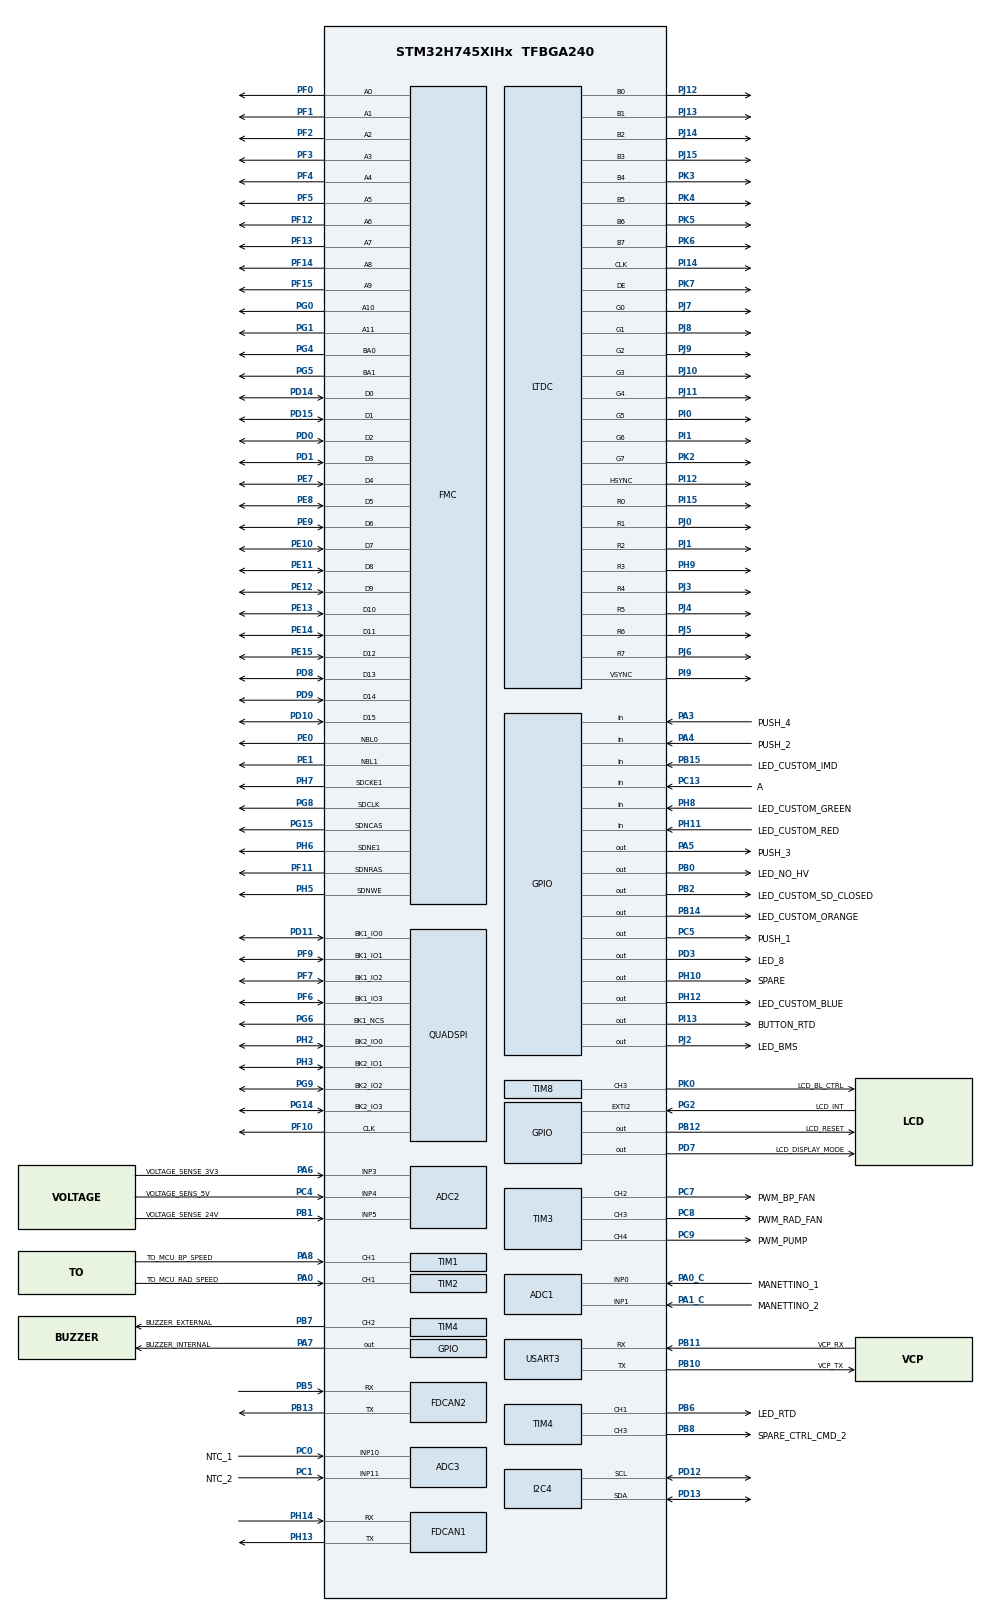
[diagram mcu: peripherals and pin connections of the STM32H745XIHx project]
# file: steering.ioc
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ADC1.Channel-1\#ChannelRegularConversion=ADC_CHANNEL_1
ADC1.NbrOfConversionFlag=1
ADC1.OffsetNumber-1\#ChannelRegularConversion=ADC_OFFSET_NONE
ADC1.OffsetSignedSaturation-1\#ChannelRegularConversion=DISABLE
ADC1.Rank-1\#ChannelRegularConversion=1
ADC1.SamplingTime-1\#ChannelRegularConversion=ADC_SAMPLETIME_1CYCLE_5
ADC1.master=1
ADC2.Channel-0\#ChannelRegularConversion=ADC_CHANNEL_3
ADC2.NbrOfConversionFlag=1
ADC2.OffsetNumber-0\#ChannelRegularConversion=ADC_OFFSET_NONE
ADC2.OffsetSignedSaturation-0\#ChannelRegularConversion=DISABLE
ADC2.Rank-0\#ChannelRegularConversion=1
ADC2.SamplingTime-0\#ChannelRegularConversion=ADC_SAMPLETIME_1CYCLE_5
ADC3.Channel-0\#ChannelRegularConversion=ADC_CHANNEL_10
ADC3.NbrOfConversionFlag=1
ADC3.OffsetNumber-0\#ChannelRegularConversion=ADC_OFFSET_NONE
ADC3.OffsetSignedSaturation-0\#ChannelRegularConversion=DISABLE
ADC3.Rank-0\#ChannelRegularConversion=1
ADC3.SamplingTime-0\#ChannelRegularConversion=ADC_SAMPLETIME_1CYCLE_5
CORTEX_M7.AccessPermission-Cortex_Memory_Protection_Unit_Region1_Settings=MPU_REGION_FULL_ACCESS
CORTEX_M7.AccessPermission-Cortex_Memory_Protection_Unit_Region2_Settings=MPU_REGION_FULL_ACCESS
CORTEX_M7.BaseAddress-Cortex_Memory_Protection_Unit_Region1_Settings=0xD0000000
CORTEX_M7.BaseAddress-Cortex_Memory_Protection_Unit_Region2_Settings=0x90000000
CORTEX_M7.CPU_DCache=Enabled
CORTEX_M7.CPU_ICache=Enabled
CORTEX_M7.DisableExec-Cortex_Memory_Protection_Unit_Region0_Settings=MPU_INSTRUCTION_ACCESS_DISABLE
CORTEX_M7.DisableExec-Cortex_Memory_Protection_Unit_Region2_Settings=MPU_INSTRUCTION_ACCESS_DISABLE
CORTEX_M7.Enable-Cortex_Memory_Protection_Unit_Region0_Settings=MPU_REGION_ENABLE
CORTEX_M7.Enable-Cortex_Memory_Protection_Unit_Region1_Settings=MPU_REGION_ENABLE
CORTEX_M7.Enable-Cortex_Memory_Protection_Unit_Region2_Settings=MPU_REGION_ENABLE
CORTEX_M7.IsBufferable-Cortex_Memory_Protection_Unit_Region2_Settings=MPU_ACCESS_BUFFERABLE
CORTEX_M7.IsCacheable-Cortex_Memory_Protection_Unit_Region1_Settings=MPU_ACCESS_CACHEABLE
CORTEX_M7.IsCacheable-Cortex_Memory_Protection_Unit_Region2_Settings=MPU_ACCESS_CACHEABLE
CORTEX_M7.IsShareable-Cortex_Memory_Protection_Unit_Region0_Settings=MPU_ACCESS_SHAREABLE
CORTEX_M7.IsShareable-Cortex_Memory_Protection_Unit_Region2_Settings=MPU_ACCESS_SHAREABLE
CORTEX_M7.MPU_Control=MPU_PRIVILEGED_DEFAULT
CORTEX_M7.Size-Cortex_Memory_Protection_Unit_Region0_Settings=MPU_REGION_SIZE_4GB
CORTEX_M7.Size-Cortex_Memory_Protection_Unit_Region1_Settings=MPU_REGION_SIZE_32MB
CORTEX_M7.Size-Cortex_Memory_Protection_Unit_Region2_Settings=MPU_REGION_SIZE_128MB
CORTEX_M7.SubRegionDisable-Cortex_Memory_Protection_Unit_Region0_Settings=0x87
CORTEX_M7.TypeExtField-Cortex_Memory_Protection_Unit_Region2_Settings=MPU_TEX_LEVEL1
CortexM4.IPs=FATFS_M4\:I,FREERTOS_M4\:I,IWDG2\:I,RCC,USB_DEVICE_M4\:I,USB_HOST_M4\:I,WWDG2\:I,DMA,BDMA,MDMA,NVIC2\:I,DEBUG,PDM2PCM_M4\:I,PWR,RESMGR_UTILITY,SYS_M4\:I,CORTEX_M4\:I,OPENAMP_M4\:I,VREFBUF,GPIO
CortexM4.Pins=PD3
CortexM7.IPs=FATFS_M7\:I,FREERTOS_M7\:I,IWDG1\:I,RCC\:I,USB_DEVICE_M7\:I,USB_HOST_M7\:I,WWDG1\:I,DMA\:I,BDMA\:I,MDMA\:I,NVIC1\:I,CORTEX_M7\:I,DEBUG\:I,PDM2PCM_M7\:I,PWR\:I,RESMGR_UTILITY\:I,SYS\:I,OPENAMP_M7\:I,VREFBUF\:I,QUADSPI\:I,USART3\:I,LTDC\:I,FMC\:I,TIM8\:I,DMA2D\:I,I2C4\:I,GPIO\:I,FDCAN2\:I,FDCAN1\:I,TIM1\:I,TIM2\:I,TIM3\:I,TIM4\:I,ADC1\:I,ADC2\:I,ADC3\:I
CortexM7.Pins=PD7,PC13,PI13,PG2,PJ2,PB12
FDCAN1.CalculateBaudRateNominal=1499999
FDCAN1.CalculateTimeBitNominal=666
FDCAN1.CalculateTimeQuantumNominal=133.33333333333334
FDCAN2.CalculateBaudRateNominal=1499999
FDCAN2.CalculateTimeBitNominal=666
FDCAN2.CalculateTimeQuantumNominal=133.33333333333334
FMC.CASLatency1=FMC_SDRAM_CAS_LATENCY_3
FMC.ExitSelfRefreshDelay1=7
FMC.LoadToActiveDelay1=2
FMC.RCDDelay1=2
FMC.RPDelay1=2
FMC.ReadBurst1=FMC_SDRAM_RBURST_ENABLE
FMC.RowCycleDelay1=7
FMC.SDClockPeriod1=FMC_SDRAM_CLOCK_PERIOD_2
FMC.SelfRefreshTime1=4
FMC.WriteRecoveryTime1=3
I2C4.CustomTiming=Disabled
I2C4.Speed=100
I2C4.Timing=0x307075B1
LTDC.ActiveH=272
LTDC.ActiveW=480
LTDC.Alpha_L0=255
LTDC.BlendingFactor1_L0=LTDC_BLENDING_FACTOR1_PAxCA
LTDC.BlendingFactor2_L0=LTDC_BLENDING_FACTOR2_PAxCA
LTDC.Blue=255
LTDC.FBStartAdress_L0=0xd0000000
LTDC.Green=255
LTDC.Green_L0=0
LTDC.HBP=13
LTDC.HFP=32
LTDC.HSync=41
LTDC.ImageHeight_L0=272
LTDC.ImageWidth_L0=480
LTDC.Layers=0
LTDC.Red=0
LTDC.VSync=10
LTDC.WindowX1_L0=480
LTDC.WindowY1_L0=272
Mcu.Family=STM32H7
Mcu.Name=STM32H745XIHx
Mcu.Package=TFBGA240
Mdma.MDMA_Channel0.Request0=SW
Mdma.MDMA_Channel0.RequestsNb=1
Mdma.MDMA_Channel0.SW.0.BlockCount=0
Mdma.MDMA_Channel0.SW.0.BlockDataLength=0
Mdma.MDMA_Channel0.SW.0.BufferTransferLength=128
Mdma.MDMA_Channel0.SW.0.CircularMode=MDMA_LINEAR_LIST
Mdma.MDMA_Channel0.SW.0.DataAlignment=MDMA_DATAALIGN_PACKENABLE
Mdma.MDMA_Channel0.SW.0.DestBlockAddressOffset=0
Mdma.MDMA_Channel0.SW.0.DestBurst=MDMA_DEST_BURST_SINGLE
Mdma.MDMA_Channel0.SW.0.DestDataSize=MDMA_DEST_DATASIZE_WORD
Mdma.MDMA_Channel0.SW.0.DestinationInc=MDMA_DEST_INC_WORD
Mdma.MDMA_Channel0.SW.0.DstAddress=0
Mdma.MDMA_Channel0.SW.0.Endianness=MDMA_LITTLE_ENDIANNESS_PRESERVE
Mdma.MDMA_Channel0.SW.0.Instance=MDMA_Channel0
Mdma.MDMA_Channel0.SW.0.MaskAddress=0
Mdma.MDMA_Channel0.SW.0.MaskData=0
Mdma.MDMA_Channel0.SW.0.Priority=MDMA_PRIORITY_HIGH
Mdma.MDMA_Channel0.SW.0.Rank=First
Mdma.MDMA_Channel0.SW.0.SourceBlockAddressOffset=0
Mdma.MDMA_Channel0.SW.0.SourceBurst=MDMA_SOURCE_BURST_SINGLE
Mdma.MDMA_Channel0.SW.0.SourceDataSize=MDMA_SRC_DATASIZE_WORD
Mdma.MDMA_Channel0.SW.0.SourceInc=MDMA_SRC_INC_WORD
Mdma.MDMA_Channel0.SW.0.SrcAddress=0
Mdma.MDMA_Channel0.SW.0.TransferTriggerMode=MDMA_BLOCK_TRANSFER
Mdma.RequestSet0=MDMA_Channel0
Mdma.RequestSetsNb=1
NVIC1.EXTI2_IRQn=true\:0\:0\:false\:false\:true\:true\:true\:true
NVIC1.MDMA_IRQn=true\:0\:0\:false\:false\:true\:false\:true\:true
NVIC1.PriorityGroup=NVIC_PRIORITYGROUP_4
NVIC1.QUADSPI_IRQn=true\:15\:0\:true\:false\:true\:true\:true\:true
NVIC2.PriorityGroup=NVIC_PRIORITYGROUP_4
PA0.GPIO_Label=TO_MCU_RAD_SPEED
PA0.PinAttribute=CortexM7
PA0.Signal=S_TIM2_CH1_ETR
PA0_C.GPIO_Label=MANETTINO_1
PA0_C.PinAttribute=CortexM7
PA0_C.Signal=ADCx_INP0
PA13\ (JTMS/SWDIO).Mode=JTAG_4_pins
PA13\ (JTMS/SWDIO).PinAttribute=CortexM7
PA13\ (JTMS/SWDIO).Signal=DEBUG_JTMS-SWDIO
PA14\ (JTCK/SWCLK).Mode=JTAG_4_pins
PA14\ (JTCK/SWCLK).PinAttribute=CortexM7
PA14\ (JTCK/SWCLK).Signal=DEBUG_JTCK-SWCLK
PA15\ (JTDI).Mode=JTAG_4_pins
PA15\ (JTDI).PinAttribute=CortexM7
PA15\ (JTDI).Signal=DEBUG_JTDI
PA1_C.GPIO_Label=MANETTINO_2
PA1_C.PinAttribute=CortexM7
PA1_C.Signal=ADCx_INP1
PA3.GPIO_Label=PUSH_4
PA3.PinAttribute=Free
PA3.Signal=GPIO_Input
PA4.GPIO_Label=PUSH_2
PA4.PinAttribute=Free
PA4.Signal=GPIO_Input
PA5.GPIO_Label=PUSH_3
PA5.PinAttribute=Free
PA5.Signal=GPIO_Output
PA6.GPIO_Label=VOLTAGE_SENSE_3V3
PA6.PinAttribute=CortexM7
PA6.Signal=ADCx_INP3
PA7.GPIO_Label=BUZZER_INTERNAL
PA7.PinAttribute=Free
PA7.Signal=GPIO_Output
PA8.GPIO_Label=TO_MCU_BP_SPEED
PA8.PinAttribute=CortexM7
PA8.Signal=S_TIM1_CH1
PB0.GPIO_Label=LED_NO_HV
PB0.PinAttribute=Free
PB0.Signal=GPIO_Output
PB1.GPIO_Label=VOLTAGE_SENSE_24V
PB1.PinAttribute=CortexM7
PB1.Signal=ADCx_INP5
PB10.GPIO_Label=VCP_TX
PB10.Mode=Asynchronous
PB10.PinAttribute=CortexM7
PB10.Signal=USART3_TX
PB11.GPIO_Label=VCP_RX
PB11.Mode=Asynchronous
PB11.PinAttribute=CortexM7
PB11.Signal=USART3_RX
PB12.GPIO_Label=LCD_RESET
PB12.PinAttribute=CortexM7
PB12.PinState=GPIO_PIN_SET
PB12.Signal=GPIO_Output
PB13.Mode=FDCAN_Activate
PB13.PinAttribute=CortexM7
PB13.Signal=FDCAN2_TX
PB14.GPIO_Label=LED_CUSTOM_ORANGE
PB14.PinAttribute=Free
PB14.Signal=GPIO_Output
PB15.GPIO_Label=LED_CUSTOM_IMD
PB15.PinAttribute=Free
PB15.Signal=GPIO_Input
PB2.GPIO_Label=LED_CUSTOM_SD_CLOSED
PB2.PinAttribute=Free
PB2.Signal=GPIO_Output
PB3\ (JTDO/TRACESWO).Mode=JTAG_4_pins
PB3\ (JTDO/TRACESWO).PinAttribute=CortexM7
PB3\ (JTDO/TRACESWO).Signal=DEBUG_JTDO-SWO
PB5.Mode=FDCAN_Activate
PB5.PinAttribute=CortexM7
PB5.Signal=FDCAN2_RX
PB6.GPIO_Label=LED_RTD
PB6.PinAttribute=CortexM7
PB6.Signal=S_TIM4_CH1
PB7.GPIO_Label=BUZZER_EXTERNAL
PB7.PinAttribute=CortexM7
PB7.Signal=S_TIM4_CH2
PB8.GPIO_Label=SPARE_CTRL_CMD_2
PB8.PinAttribute=CortexM7
PB8.Signal=S_TIM4_CH3
PC0.GPIO_Label=NTC_1
PC0.PinAttribute=CortexM7
PC0.Signal=ADCx_INP10
PC1.GPIO_Label=NTC_2
PC1.PinAttribute=CortexM7
PC1.Signal=ADCx_INP11
PC13.GPIO_Label=A
PC13.PinAttribute=CortexM7
PC13.Signal=GPIO_Input
PC14-OSC32_IN\ (OSC32_IN).GPIO_Label=OSC32_IN
PC14-OSC32_IN\ (OSC32_IN).Mode=LSE-External-Clock-Source
PC14-OSC32_IN\ (OSC32_IN).PinAttribute=CortexM7
PC14-OSC32_IN\ (OSC32_IN).Signal=RCC_OSC32_IN
PC4.GPIO_Label=VOLTAGE_SENS_5V
PC4.PinAttribute=CortexM7
PC4.Signal=ADCx_INP4
PC5.GPIO_Label=PUSH_1
PC5.PinAttribute=Free
PC5.Signal=GPIO_Output
PC7.GPIO_Label=PWM_BP_FAN
PC7.PinAttribute=CortexM7
PC7.Signal=S_TIM3_CH2
PC8.GPIO_Label=PWM_RAD_FAN
PC8.PinAttribute=CortexM7
PC8.Signal=S_TIM3_CH3
PC9.GPIO_Label=PWM_PUMP
PC9.PinAttribute=CortexM7
PC9.Signal=S_TIM3_CH4
PD0.PinAttribute=CortexM7
PD0.Signal=FMC_D2_DA2
PD1.PinAttribute=CortexM7
PD1.Signal=FMC_D3_DA3
PD10.PinAttribute=CortexM7
PD10.Signal=FMC_D15_DA15
PD11.GPIO_Speed=GPIO_SPEED_FREQ_VERY_HIGH
PD11.Mode=Dual_Bank
PD11.PinAttribute=CortexM7
PD11.Signal=QUADSPI_BK1_IO0
PD12.Mode=I2C
PD12.PinAttribute=CortexM7
PD12.Signal=I2C4_SCL
PD13.Mode=I2C
PD13.PinAttribute=CortexM7
PD13.Signal=I2C4_SDA
PD14.PinAttribute=CortexM7
PD14.Signal=FMC_D0_DA0
PD15.PinAttribute=CortexM7
PD15.Signal=FMC_D1_DA1
PD3.GPIO_Label=LED_8
PD3.PinAttribute=CortexM4
PD3.Signal=GPIO_Output
PD7.GPIO_Label=LCD_DISPLAY_MODE
PD7.GPIO_Speed=GPIO_SPEED_FREQ_LOW
PD7.PinAttribute=CortexM7
PD7.PinState=GPIO_PIN_SET
PD7.Signal=GPIO_Output
PD8.PinAttribute=CortexM7
PD8.Signal=FMC_D13_DA13
PD9.PinAttribute=CortexM7
PD9.Signal=FMC_D14_DA14
PE0.PinAttribute=CortexM7
PE0.Signal=FMC_NBL0
PE1.PinAttribute=CortexM7
PE1.Signal=FMC_NBL1
PE10.PinAttribute=CortexM7
PE10.Signal=FMC_D7_DA7
PE11.PinAttribute=CortexM7
PE11.Signal=FMC_D8_DA8
PE12.PinAttribute=CortexM7
PE12.Signal=FMC_D9_DA9
PE13.PinAttribute=CortexM7
PE13.Signal=FMC_D10_DA10
PE14.PinAttribute=CortexM7
PE14.Signal=FMC_D11_DA11
PE15.PinAttribute=CortexM7
PE15.Signal=FMC_D12_DA12
PE7.PinAttribute=CortexM7
PE7.Signal=FMC_D4_DA4
PE8.PinAttribute=CortexM7
PE8.Signal=FMC_D5_DA5
PE9.PinAttribute=CortexM7
PE9.Signal=FMC_D6_DA6
PF0.PinAttribute=CortexM7
PF0.Signal=FMC_A0
PF1.PinAttribute=CortexM7
PF1.Signal=FMC_A1
PF10.GPIO_Speed=GPIO_SPEED_FREQ_VERY_HIGH
PF10.Mode=Dual_Bank
PF10.PinAttribute=CortexM7
PF10.Signal=QUADSPI_CLK
PF11.PinAttribute=CortexM7
PF11.Signal=FMC_SDNRAS
PF12.PinAttribute=CortexM7
PF12.Signal=FMC_A6
PF13.PinAttribute=CortexM7
PF13.Signal=FMC_A7
PF14.PinAttribute=CortexM7
PF14.Signal=FMC_A8
PF15.PinAttribute=CortexM7
PF15.Signal=FMC_A9
PF2.PinAttribute=CortexM7
PF2.Signal=FMC_A2
PF3.PinAttribute=CortexM7
PF3.Signal=FMC_A3
PF4.PinAttribute=CortexM7
PF4.Signal=FMC_A4
PF5.PinAttribute=CortexM7
PF5.Signal=FMC_A5
PF6.GPIO_Speed=GPIO_SPEED_FREQ_VERY_HIGH
PF6.Mode=Dual_Bank
PF6.PinAttribute=CortexM7
PF6.Signal=QUADSPI_BK1_IO3
PF7.GPIO_Speed=GPIO_SPEED_FREQ_VERY_HIGH
PF7.Mode=Dual_Bank
PF7.PinAttribute=CortexM7
PF7.Signal=QUADSPI_BK1_IO2
PF9.GPIO_Speed=GPIO_SPEED_FREQ_VERY_HIGH
PF9.Mode=Dual_Bank
PF9.PinAttribute=CortexM7
PF9.Signal=QUADSPI_BK1_IO1
PG0.PinAttribute=CortexM7
PG0.Signal=FMC_A10
PG1.PinAttribute=CortexM7
PG1.Signal=FMC_A11
PG14.GPIO_Speed=GPIO_SPEED_FREQ_VERY_HIGH
PG14.Mode=Dual_Bank
PG14.PinAttribute=CortexM7
PG14.Signal=QUADSPI_BK2_IO3
PG15.PinAttribute=CortexM7
PG15.Signal=FMC_SDNCAS
PG2.GPIO_Label=LCD_INT
PG2.PinAttribute=CortexM7
PG2.Signal=GPXTI2
PG4.PinAttribute=CortexM7
PG4.Signal=FMC_A14_BA0
PG5.PinAttribute=CortexM7
PG5.Signal=FMC_A15_BA1
PG6.GPIO_PuPd=GPIO_PULLUP
PG6.GPIO_Speed=GPIO_SPEED_FREQ_VERY_HIGH
PG6.Mode=Enable Chip Select 1 for both banks
PG6.PinAttribute=CortexM7
PG6.Signal=QUADSPI_BK1_NCS
PG8.PinAttribute=CortexM7
PG8.Signal=FMC_SDCLK
PG9.GPIO_Speed=GPIO_SPEED_FREQ_VERY_HIGH
PG9.Mode=Dual_Bank
PG9.PinAttribute=CortexM7
PG9.Signal=QUADSPI_BK2_IO2
PH0-OSC_IN\ (PH0).GPIO_Label=OSC_IN
PH0-OSC_IN\ (PH0).Mode=HSE-External-Clock-Source
PH0-OSC_IN\ (PH0).PinAttribute=CortexM7
PH0-OSC_IN\ (PH0).Signal=RCC_OSC_IN
PH10.GPIO_Label=SPARE
PH10.PinAttribute=Free
PH10.Signal=GPIO_Output
PH11.GPIO_Label=LED_CUSTOM_RED
PH11.PinAttribute=Free
PH11.Signal=GPIO_Input
PH12.GPIO_Label=LED_CUSTOM_BLUE
PH12.PinAttribute=Free
PH12.Signal=GPIO_Output
PH13.Mode=FDCAN_Activate
PH13.PinAttribute=CortexM7
PH13.Signal=FDCAN1_TX
PH14.Mode=FDCAN_Activate
PH14.PinAttribute=CortexM7
PH14.Signal=FDCAN1_RX
PH2.GPIO_Speed=GPIO_SPEED_FREQ_VERY_HIGH
PH2.Mode=Dual_Bank
PH2.PinAttribute=CortexM7
PH2.Signal=QUADSPI_BK2_IO0
PH3.GPIO_Speed=GPIO_SPEED_FREQ_VERY_HIGH
PH3.Mode=Dual_Bank
PH3.PinAttribute=CortexM7
PH3.Signal=QUADSPI_BK2_IO1
PH5.PinAttribute=CortexM7
PH5.Signal=FMC_SDNWE
PH6.Mode=SdramChipSelect2_1
PH6.PinAttribute=CortexM7
PH6.Signal=FMC_SDNE1
PH7.Mode=SdramChipSelect2_1
PH7.PinAttribute=CortexM7
PH7.Signal=FMC_SDCKE1
PH8.GPIO_Label=LED_CUSTOM_GREEN
PH8.PinAttribute=Free
PH8.Signal=GPIO_Input
PH9.Mode=RGB888
PH9.PinAttribute=CortexM7
PH9.Signal=LTDC_R3
PI0.Mode=RGB888
PI0.PinAttribute=CortexM7
PI0.Signal=LTDC_G5
PI1.Mode=RGB888
PI1.PinAttribute=CortexM7
PI1.Signal=LTDC_G6
PI12.Mode=RGB888
PI12.PinAttribute=CortexM7
PI12.Signal=LTDC_HSYNC
PI13.GPIO_Label=BUTTON_RTD
PI13.PinAttribute=CortexM7
PI13.Signal=GPIO_Output
PI14.Mode=RGB888
PI14.PinAttribute=CortexM7
PI14.Signal=LTDC_CLK
PI15.Mode=RGB888
PI15.PinAttribute=CortexM7
PI15.Signal=LTDC_R0
PI9.Mode=RGB888
PI9.PinAttribute=CortexM7
PI9.Signal=LTDC_VSYNC
PJ0.Mode=RGB888
PJ0.PinAttribute=CortexM7
PJ0.Signal=LTDC_R1
PJ1.Mode=RGB888
PJ1.PinAttribute=CortexM7
PJ1.Signal=LTDC_R2
PJ10.Mode=RGB888
PJ10.PinAttribute=CortexM7
PJ10.Signal=LTDC_G3
PJ11.Mode=RGB888
PJ11.PinAttribute=CortexM7
PJ11.Signal=LTDC_G4
PJ12.Mode=RGB888
PJ12.PinAttribute=CortexM7
PJ12.Signal=LTDC_B0
PJ13.Mode=RGB888
PJ13.PinAttribute=CortexM7
PJ13.Signal=LTDC_B1
PJ14.Mode=RGB888
PJ14.PinAttribute=CortexM7
PJ14.Signal=LTDC_B2
PJ15.Mode=RGB888
PJ15.PinAttribute=CortexM7
PJ15.Signal=LTDC_B3
PJ2.GPIO_Label=LED_BMS
PJ2.PinAttribute=CortexM7
PJ2.Signal=GPIO_Output
PJ3.Mode=RGB888
PJ3.PinAttribute=CortexM7
PJ3.Signal=LTDC_R4
PJ4.Mode=RGB888
PJ4.PinAttribute=CortexM7
PJ4.Signal=LTDC_R5
PJ5.Mode=RGB888
PJ5.PinAttribute=CortexM7
PJ5.Signal=LTDC_R6
PJ6.Mode=RGB888
PJ6.PinAttribute=CortexM7
PJ6.Signal=LTDC_R7
PJ7.Mode=RGB888
PJ7.PinAttribute=CortexM7
PJ7.Signal=LTDC_G0
PJ8.Mode=RGB888
PJ8.PinAttribute=CortexM7
PJ8.Signal=LTDC_G1
PJ9.Mode=RGB888
PJ9.PinAttribute=CortexM7
PJ9.Signal=LTDC_G2
PK0.GPIO_Label=LCD_BL_CTRL
PK0.GPIO_Speed=GPIO_SPEED_FREQ_MEDIUM
PK0.PinAttribute=CortexM7
PK0.Signal=S_TIM8_CH3
PK2.Mode=RGB888
PK2.PinAttribute=CortexM7
PK2.Signal=LTDC_G7
PK3.Mode=RGB888
PK3.PinAttribute=CortexM7
PK3.Signal=LTDC_B4
PK4.Mode=RGB888
PK4.PinAttribute=CortexM7
PK4.Signal=LTDC_B5
PK5.Mode=RGB888
PK5.PinAttribute=CortexM7
PK5.Signal=LTDC_B6
PK6.Mode=RGB888
PK6.PinAttribute=CortexM7
PK6.Signal=LTDC_B7
PK7.Mode=RGB888
PK7.PinAttribute=CortexM7
PK7.Signal=LTDC_DE
ProjectManager.HeapSize=M4-0x200,M7-0x1000
ProjectManager.StackSize=M4-0x400,M7-0x2000
ProjectManager.TargetToolchain=STM32CubeIDE
QUADSPI.ChipSelectHighTime=QSPI_CS_HIGH_TIME_4_CYCLE
QUADSPI.ClockPrescaler=3
QUADSPI.FlashSize=26
RCC.ADCFreq_Value=75000000
RCC.APB1Freq_Value=120000000
RCC.APB2Freq_Value=120000000
RCC.APB3Freq_Value=120000000
RCC.APB4Freq_Value=120000000
RCC.CortexFreq_Value=480000000
RCC.D1PPRE=RCC_APB3_DIV2
RCC.D2PPRE1=RCC_APB1_DIV2
RCC.D2PPRE2=RCC_APB2_DIV2
RCC.D3PPRE=RCC_APB4_DIV2
RCC.DIVM1=5
RCC.DIVM2=2
RCC.DIVM3=5
RCC.DIVN1=192
RCC.DIVN2=12
RCC.DIVN3=160
RCC.DIVQ1=8
RCC.DIVR1=4
RCC.DIVR3=83
RCC.HCLKFreq_Value=240000000
RCC.HPRE=RCC_HCLK_DIV2
RCC.PLL2FRACN=0
RCC.PLL3FRACN=0
RCC.PLLFRACN=0
RCC.PLLSourceVirtual=RCC_PLLSOURCE_HSE
RCC.PWR_Regulator_Voltage_Scale=PWR_REGULATOR_VOLTAGE_SCALE0
RCC.SYSCLKFreq_VALUE=480000000
RCC.SYSCLKSource=RCC_SYSCLKSOURCE_PLLCLK
RCC.SupplySource=PWR_DIRECT_SMPS_SUPPLY
RCC.USBFreq_Value=120000000
SH.ADCx_INP0.0=ADC1_INP0,IN0-Single-Ended
SH.ADCx_INP1.0=ADC1_INP1,IN1-Single-Ended
SH.ADCx_INP10.0=ADC3_INP10,IN10-Single-Ended
SH.ADCx_INP11.0=ADC3_INP11,IN11-Single-Ended
SH.ADCx_INP3.0=ADC2_INP3,IN3-Single-Ended
SH.ADCx_INP4.0=ADC2_INP4,IN4-Single-Ended
SH.ADCx_INP5.0=ADC2_INP5,IN5-Single-Ended
SH.FMC_A0.0=FMC_A0,12b-sda1
SH.FMC_A1.0=FMC_A1,12b-sda1
SH.FMC_A10.0=FMC_A10,12b-sda1
SH.FMC_A11.0=FMC_A11,12b-sda1
SH.FMC_A14_BA0.0=FMC_BA0,FourSdramBanks1
SH.FMC_A15_BA1.0=FMC_BA1,FourSdramBanks1
SH.FMC_A2.0=FMC_A2,12b-sda1
SH.FMC_A3.0=FMC_A3,12b-sda1
SH.FMC_A4.0=FMC_A4,12b-sda1
SH.FMC_A5.0=FMC_A5,12b-sda1
SH.FMC_A6.0=FMC_A6,12b-sda1
SH.FMC_A7.0=FMC_A7,12b-sda1
SH.FMC_A8.0=FMC_A8,12b-sda1
SH.FMC_A9.0=FMC_A9,12b-sda1
SH.FMC_D0_DA0.0=FMC_D0,sd-16b-d1
SH.FMC_D10_DA10.0=FMC_D10,sd-16b-d1
SH.FMC_D11_DA11.0=FMC_D11,sd-16b-d1
SH.FMC_D12_DA12.0=FMC_D12,sd-16b-d1
SH.FMC_D13_DA13.0=FMC_D13,sd-16b-d1
SH.FMC_D14_DA14.0=FMC_D14,sd-16b-d1
SH.FMC_D15_DA15.0=FMC_D15,sd-16b-d1
SH.FMC_D1_DA1.0=FMC_D1,sd-16b-d1
SH.FMC_D2_DA2.0=FMC_D2,sd-16b-d1
SH.FMC_D3_DA3.0=FMC_D3,sd-16b-d1
SH.FMC_D4_DA4.0=FMC_D4,sd-16b-d1
SH.FMC_D5_DA5.0=FMC_D5,sd-16b-d1
SH.FMC_D6_DA6.0=FMC_D6,sd-16b-d1
SH.FMC_D7_DA7.0=FMC_D7,sd-16b-d1
SH.FMC_D8_DA8.0=FMC_D8,sd-16b-d1
SH.FMC_D9_DA9.0=FMC_D9,sd-16b-d1
SH.FMC_NBL0.0=FMC_NBL0,Sd2ByteEnable1
SH.FMC_NBL1.0=FMC_NBL1,Sd2ByteEnable1
SH.FMC_SDCLK.0=FMC_SDCLK,12b-sda1
SH.FMC_SDNCAS.0=FMC_SDNCAS,12b-sda1
SH.FMC_SDNRAS.0=FMC_SDNRAS,12b-sda1
SH.FMC_SDNWE.0=FMC_SDNWE,12b-sda1
SH.S_TIM1_CH1.0=TIM1_CH1,PWM_Input_1
SH.S_TIM2_CH1_ETR.0=TIM2_CH1,PWM_Input_1
SH.S_TIM3_CH2.0=TIM3_CH2,PWM Generation2 CH2
SH.S_TIM3_CH3.0=TIM3_CH3,PWM Generation3 CH3
SH.S_TIM3_CH4.0=TIM3_CH4,PWM Generation4 CH4
SH.S_TIM4_CH1.0=TIM4_CH1,PWM Generation1 CH1
SH.S_TIM4_CH2.0=TIM4_CH2,PWM Generation2 CH2
SH.S_TIM4_CH3.0=TIM4_CH3,PWM Generation3 CH3
SH.S_TIM8_CH3.0=TIM8_CH3,PWM Generation3 CH3
TIM3.Channel-PWM\ Generation2\ CH2=TIM_CHANNEL_2
TIM3.Channel-PWM\ Generation3\ CH3=TIM_CHANNEL_3
TIM3.Channel-PWM\ Generation4\ CH4=TIM_CHANNEL_4
TIM4.Channel-PWM\ Generation1\ CH1=TIM_CHANNEL_1
TIM4.Channel-PWM\ Generation2\ CH2=TIM_CHANNEL_2
TIM4.Channel-PWM\ Generation3\ CH3=TIM_CHANNEL_3
TIM8.Channel-PWM\ Generation3\ CH3=TIM_CHANNEL_3
TIM8.Period=50000
TIM8.Prescaler=4
USART3.VirtualMode-Asynchronous=VM_ASYNC
VP_DMA2D_VS_DMA2D.Mode=DMA2D_Activate
VP_SYS_M4_VS_Systick.Mode=SysTick
VP_TIM4_VS_ClockSourceINT.Mode=Internal
board=STM32H745I-DISCO

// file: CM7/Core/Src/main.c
/* USER CODE BEGIN Header */
/**
  ******************************************************************************
  * @file           : main.c
  * @brief          : Main program body
  ******************************************************************************
  * @attention
  *
  * Copyright (c) 2022 STMicroelectronics.
  * All rights reserved.
  *
  * This software is licensed under terms that can be found in the LICENSE file
  * in the root directory of this software component.
  * If no LICENSE file comes with this software, it is provided AS-IS.
  *
  ******************************************************************************
  */
/* USER CODE END Header */
#include "main.h"
#include "adc.h"
#include "dma2d.h"
#include "fdcan.h"
#include "i2c.h"
#include "ltdc.h"
#include "mdma.h"
#include "quadspi.h"
#include "tim.h"
#include "usart.h"
#include "gpio.h"
#include "fmc.h"

/* USER CODE BEGIN Includes */
#include <stdio.h>
#include "driver/qspi.h"
#include "lvgl/lvgl.h"
#include "lvgl/demos/lv_demos.h"
#include "sw/lvgl_port_lcd.h"
#include "sw/lvgl_port_touchpad.h"
/* USER CODE END Includes */

/* USER CODE BEGIN PD */

#ifndef HSEM_ID_0
#define HSEM_ID_0 (0U) /* HW semaphore 0*/
#endif
/* USER CODE END PD */

void SystemClock_Config(void);
void PeriphCommonClock_Config(void);
static void MPU_Config(void);

/* USER CODE BEGIN 0 */
int __io_putchar(int ch)
{
  HAL_UART_Transmit(&huart3, (uint8_t *) &ch, 1, HAL_MAX_DELAY);
  return 1;
}

int __io_getchar(void)
{
  uint8_t ch = 0;
  HAL_UART_Receive(&huart3, &ch, 1, HAL_MAX_DELAY);
  return ch;
}

uint64_t __time_uptime(void)
{
  return HAL_GetTick();
}
/* USER CODE END 0 */

int main(void)
{
/* USER CODE BEGIN Boot_Mode_Sequence_0 */
  int32_t timeout;
/* USER CODE END Boot_Mode_Sequence_0 */

  /* MPU Configuration--------------------------------------------------------*/
  MPU_Config();

  /* Enable I-Cache---------------------------------------------------------*/
  SCB_EnableICache();

  /* Enable D-Cache---------------------------------------------------------*/
  SCB_EnableDCache();

/* USER CODE BEGIN Boot_Mode_Sequence_1 */
  /* Wait until CPU2 boots and enters in stop mode or timeout*/
  timeout = 0xFFFF;
  while((__HAL_RCC_GET_FLAG(RCC_FLAG_D2CKRDY) != RESET) && (timeout-- > 0));
  if ( timeout < 0 )
  {
  Error_Handler();
  }
/* USER CODE END Boot_Mode_Sequence_1 */
  /* MCU Configuration--------------------------------------------------------*/

  /* Reset of all peripherals, Initializes the Flash interface and the Systick. */
  HAL_Init();

  /* Configure the system clock */
  SystemClock_Config();

/* Configure the peripherals common clocks */
  PeriphCommonClock_Config();
/* USER CODE BEGIN Boot_Mode_Sequence_2 */
/* When system initialization is finished, Cortex-M7 will release Cortex-M4 by means of
HSEM notification */
/*HW semaphore Clock enable*/
__HAL_RCC_HSEM_CLK_ENABLE();
/*Take HSEM */
HAL_HSEM_FastTake(HSEM_ID_0);
/*Release HSEM in order to notify the CPU2(CM4)*/
HAL_HSEM_Release(HSEM_ID_0,0);
/* wait until CPU2 wakes up from stop mode */
timeout = 0xFFFF;
while((__HAL_RCC_GET_FLAG(RCC_FLAG_D2CKRDY) == RESET) && (timeout-- > 0));
if ( timeout < 0 )
{
Error_Handler();
}
/* USER CODE END Boot_Mode_Sequence_2 */

  /* Initialize all configured peripherals */
  MX_GPIO_Init();
  MX_MDMA_Init();
  MX_LTDC_Init();
  MX_QUADSPI_Init();
  MX_FMC_Init();
  MX_I2C4_Init();
  MX_DMA2D_Init();
  MX_TIM8_Init();
  MX_USART3_UART_Init();
  MX_ADC1_Init();
  MX_ADC2_Init();
  MX_ADC3_Init();
  MX_FDCAN1_Init();
  MX_FDCAN2_Init();
  MX_TIM1_Init();
  MX_TIM2_Init();
  MX_TIM3_Init();
  MX_TIM4_Init();
  /* USER CODE BEGIN 2 */

  // BSP_QSPI_Init_t qspi_init;
  // qspi_init.InterfaceMode = MT25TL01G_QPI_MODE;
  // qspi_init.TransferRate = MT25TL01G_DTR_TRANSFER;
  // qspi_init.DualFlashMode = MT25TL01G_DUALFLASH_ENABLE;
  // BSP_QSPI_Init(&qspi_init);
  // BSP_QSPI_EnableMemoryMappedMode(0);

  // lv_init();
  // LCD_Init();
  // TS_Init();
  // lv_demo_widgets();
  // printf("Hello World!\n");
  /* USER CODE END 2 */

  /* Infinite loop */
  /* USER CODE BEGIN WHILE */
  while (1)
  {
		// lv_task_handler();
		// HAL_Delay(5);
    /* USER CODE END WHILE */

  }
}

void SystemClock_Config(void)
{
  RCC_OscInitTypeDef RCC_OscInitStruct = {0};
  RCC_ClkInitTypeDef RCC_ClkInitStruct = {0};

  /** Supply configuration update enable
  */
  HAL_PWREx_ConfigSupply(PWR_DIRECT_SMPS_SUPPLY);

  /** Configure the main internal regulator output voltage
  */

  while(!__HAL_PWR_GET_FLAG(PWR_FLAG_VOSRDY)) {}

  /** Macro to configure the PLL clock source
  */
  __HAL_RCC_PLL_PLLSOURCE_CONFIG(RCC_PLLSOURCE_HSE);

  /** Initializes the RCC Oscillators according to the specified parameters
  * in the RCC_OscInitTypeDef structure.
  */
  RCC_OscInitStruct.OscillatorType = RCC_OSCILLATORTYPE_HSE;
  RCC_OscInitStruct.HSEState = RCC_HSE_BYPASS;
  RCC_OscInitStruct.PLL.PLLState = RCC_PLL_ON;
  RCC_OscInitStruct.PLL.PLLSource = RCC_PLLSOURCE_HSE;
  RCC_OscInitStruct.PLL.PLLM = 5;
  RCC_OscInitStruct.PLL.PLLN = 192;
  RCC_OscInitStruct.PLL.PLLP = 2;
  RCC_OscInitStruct.PLL.PLLQ = 8;
  RCC_OscInitStruct.PLL.PLLR = 4;
  RCC_OscInitStruct.PLL.PLLRGE = RCC_PLL1VCIRANGE_2;
  RCC_OscInitStruct.PLL.PLLVCOSEL = RCC_PLL1VCOWIDE;
  RCC_OscInitStruct.PLL.PLLFRACN = 0;
  if (HAL_RCC_OscConfig(&RCC_OscInitStruct) != HAL_OK)
  {
    Error_Handler();
  }

  /** Initializes the CPU, AHB and APB buses clocks
  */
  RCC_ClkInitStruct.ClockType = RCC_CLOCKTYPE_HCLK|RCC_CLOCKTYPE_SYSCLK
                              |RCC_CLOCKTYPE_PCLK1|RCC_CLOCKTYPE_PCLK2
                              |RCC_CLOCKTYPE_D3PCLK1|RCC_CLOCKTYPE_D1PCLK1;
  RCC_ClkInitStruct.SYSCLKSource = RCC_SYSCLKSOURCE_PLLCLK;
  RCC_ClkInitStruct.SYSCLKDivider = RCC_SYSCLK_DIV1;
  RCC_ClkInitStruct.AHBCLKDivider = RCC_HCLK_DIV2;
  RCC_ClkInitStruct.APB3CLKDivider = RCC_APB3_DIV2;
  RCC_ClkInitStruct.APB1CLKDivider = RCC_APB1_DIV2;
  RCC_ClkInitStruct.APB2CLKDivider = RCC_APB2_DIV2;
  RCC_ClkInitStruct.APB4CLKDivider = RCC_APB4_DIV2;

  if (HAL_RCC_ClockConfig(&RCC_ClkInitStruct, FLASH_LATENCY_0) != HAL_OK)
  {
    Error_Handler();
  }
}

void PeriphCommonClock_Config(void)
{
  RCC_PeriphCLKInitTypeDef PeriphClkInitStruct = {0};

  /** Initializes the peripherals clock
  */
  PeriphClkInitStruct.PeriphClockSelection = RCC_PERIPHCLK_ADC;
  PeriphClkInitStruct.PLL2.PLL2M = 2;
  PeriphClkInitStruct.PLL2.PLL2N = 12;
  PeriphClkInitStruct.PLL2.PLL2P = 2;
  PeriphClkInitStruct.PLL2.PLL2Q = 2;
  PeriphClkInitStruct.PLL2.PLL2R = 2;
  PeriphClkInitStruct.PLL2.PLL2RGE = RCC_PLL2VCIRANGE_3;
  PeriphClkInitStruct.PLL2.PLL2VCOSEL = RCC_PLL2VCOMEDIUM;
  PeriphClkInitStruct.PLL2.PLL2FRACN = 0;
  PeriphClkInitStruct.AdcClockSelection = RCC_ADCCLKSOURCE_PLL2;
  if (HAL_RCCEx_PeriphCLKConfig(&PeriphClkInitStruct) != HAL_OK)
  {
    Error_Handler();
  }
}

/* MPU Configuration */

void MPU_Config(void)
{
  MPU_Region_InitTypeDef MPU_InitStruct = {0};

  /* Disables the MPU */
  HAL_MPU_Disable();

  /** Initializes and configures the Region and the memory to be protected
  */
  MPU_InitStruct.Enable = MPU_REGION_ENABLE;
  MPU_InitStruct.Number = MPU_REGION_NUMBER0;
  MPU_InitStruct.BaseAddress = 0x0;
  MPU_InitStruct.Size = MPU_REGION_SIZE_4GB;
  MPU_InitStruct.SubRegionDisable = 0x87;
  MPU_InitStruct.TypeExtField = MPU_TEX_LEVEL0;
  MPU_InitStruct.AccessPermission = MPU_REGION_NO_ACCESS;
  MPU_InitStruct.DisableExec = MPU_INSTRUCTION_ACCESS_DISABLE;
  MPU_InitStruct.IsShareable = MPU_ACCESS_SHAREABLE;
  MPU_InitStruct.IsCacheable = MPU_ACCESS_NOT_CACHEABLE;
  MPU_InitStruct.IsBufferable = MPU_ACCESS_NOT_BUFFERABLE;

  HAL_MPU_ConfigRegion(&MPU_InitStruct);

  /** Initializes and configures the Region and the memory to be protected
  */
  MPU_InitStruct.Number = MPU_REGION_NUMBER1;
  MPU_InitStruct.BaseAddress = 0xD0000000;
  MPU_InitStruct.Size = MPU_REGION_SIZE_32MB;
  MPU_InitStruct.SubRegionDisable = 0x0;
  MPU_InitStruct.AccessPermission = MPU_REGION_FULL_ACCESS;
  MPU_InitStruct.DisableExec = MPU_INSTRUCTION_ACCESS_ENABLE;
  MPU_InitStruct.IsShareable = MPU_ACCESS_NOT_SHAREABLE;
  MPU_InitStruct.IsCacheable = MPU_ACCESS_CACHEABLE;

  HAL_MPU_ConfigRegion(&MPU_InitStruct);

  /** Initializes and configures the Region and the memory to be protected
  */
  MPU_InitStruct.Number = MPU_REGION_NUMBER2;
  MPU_InitStruct.BaseAddress = 0x90000000;
  MPU_InitStruct.Size = MPU_REGION_SIZE_128MB;
  MPU_InitStruct.TypeExtField = MPU_TEX_LEVEL1;
  MPU_InitStruct.DisableExec = MPU_INSTRUCTION_ACCESS_DISABLE;
  MPU_InitStruct.IsShareable = MPU_ACCESS_SHAREABLE;
  MPU_InitStruct.IsBufferable = MPU_ACCESS_BUFFERABLE;

  HAL_MPU_ConfigRegion(&MPU_InitStruct);
  /* Enables the MPU */
  HAL_MPU_Enable(MPU_PRIVILEGED_DEFAULT);

}

void Error_Handler(void)
{
  __disable_irq();
  while (1)
  {
  }
}
